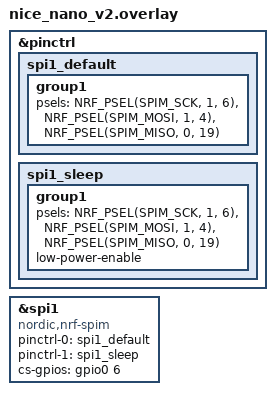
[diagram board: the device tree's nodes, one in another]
&pinctrl {
    spi1_default: spi1_default {
        group1 {
            psels = <NRF_PSEL(SPIM_SCK, 1, 6)>,  // SCK = P1.06 (D9)
                    <NRF_PSEL(SPIM_MOSI, 1, 4)>, // MOSI = P1.04 (D8)
                    <NRF_PSEL(SPIM_MISO, 0, 19)>;
        };
    };
    spi1_sleep: spi1_sleep {
        group1 {
            psels = <NRF_PSEL(SPIM_SCK, 1, 6)>,
                    <NRF_PSEL(SPIM_MOSI, 1, 4)>,
					<NRF_PSEL(SPIM_MISO, 0, 19)>;
            low-power-enable;
        };
    };
};

nice_view_spi: &spi1 {
    compatible = "nordic,nrf-spim";
    pinctrl-0 = <&spi1_default>;
    pinctrl-1 = <&spi1_sleep>;
    pinctrl-names = "default", "sleep";
    cs-gpios = <&gpio0 6 GPIO_ACTIVE_HIGH>; // CS = P0.06 (D1)
};
